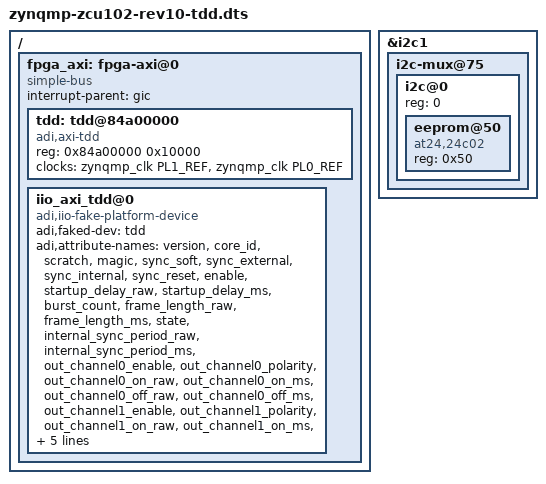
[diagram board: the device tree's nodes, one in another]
// SPDX-License-Identifier: GPL-2.0
/*
 * Analog Devices TDD Test Device Tree
 *
 * hdl_project: <tdd/zcu102>
 * board_revision: <>
 *
 * Copyright (C) 2023 Analog Devices Inc.
 */

#include "zynqmp-zcu102-rev1.0.dts"

&i2c1 {
	i2c-mux@75 {
		i2c@0 { /* HPC0 */
			#address-cells = <1>;
			#size-cells = <0>;
			reg = <0>;
			/* HPC0_IIC */
			eeprom@50 {
				compatible = "at24,24c02";
				reg = <0x50>;
			};
		};
	};
};

/ {
	fpga_axi: fpga-axi@0 {
		interrupt-parent = <&gic>;
		compatible = "simple-bus";
		#address-cells = <0x1>;
		#size-cells = <0x1>;
		ranges = <0 0 0 0xffffffff>;

		tdd: tdd@84a00000 {
			compatible = "adi,axi-tdd";
			reg = <0x84a00000 0x10000>;
			clocks = <&zynqmp_clk PL1_REF>, <&zynqmp_clk PL0_REF>;
			clock-names = "intf_clk", "s_axi_aclk";
		};

		iio_axi_tdd@0 {
			compatible = "adi,iio-fake-platform-device";
			adi,faked-dev = <&tdd>;
			adi,attribute-names =
				"version", "core_id", "scratch", "magic",
				"sync_soft", "sync_external", "sync_internal", "sync_reset",
				"enable", "startup_delay_raw", "startup_delay_ms",
				"burst_count", "frame_length_raw", "frame_length_ms",
				"state", "internal_sync_period_raw", "internal_sync_period_ms",
				"out_channel0_enable", "out_channel0_polarity",
				"out_channel0_on_raw", "out_channel0_on_ms",
				"out_channel0_off_raw", "out_channel0_off_ms",
				"out_channel1_enable", "out_channel1_polarity",
				"out_channel1_on_raw", "out_channel1_on_ms",
				"out_channel1_off_raw", "out_channel1_off_ms",
				"out_channel2_enable", "out_channel2_polarity",
				"out_channel2_on_raw", "out_channel2_on_ms",
				"out_channel2_off_raw", "out_channel2_off_ms";
			label = "axi-core-tdd";
		};
	};
};
